# RTL8710AF register map
Vendor: Realtek Semiconductor; Series: Ameba; File version: 0.1
CPU: CM3 r0p0, little endian, no MPU, no FPU, vendor SysTick, 4 interrupt priority bits
Registers are 32-bit, read-write, reset 0x0 unless marked. A register's access mark holds for its fields unless they carry their own. Offsets are from the block's base; [hi:lo] are bit positions; {n}, {i} and the like mark numbered series; 'fields as' and 'values as' point back to an identical list.

## SYSCON — System Control Registers
Base 0x40000000
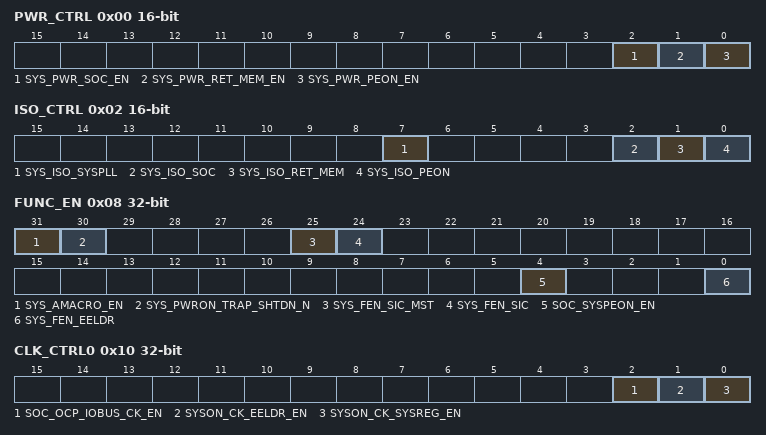
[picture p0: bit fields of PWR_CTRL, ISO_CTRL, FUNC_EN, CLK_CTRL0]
0x00 PWR_CTRL 16-bit
  [2] SYS_PWR_SOC_EN, [1] SYS_PWR_RET_MEM_EN, [0] SYS_PWR_PEON_EN
0x02 ISO_CTRL 16-bit
  [7] SYS_ISO_SYSPLL, [2] SYS_ISO_SOC, [1] SYS_ISO_RET_MEM, [0] SYS_ISO_PEON
0x08 FUNC_EN
  [31] SYS_AMACRO_EN, [30] SYS_PWRON_TRAP_SHTDN_N, [25] SYS_FEN_SIC_MST, [24] SYS_FEN_SIC, [4] SOC_SYSPEON_EN, [0] SYS_FEN_EELDR
0x10 CLK_CTRL0
  [2] SOC_OCP_IOBUS_CK_EN, [1] SYSON_CK_EELDR_EN, [0] SYSON_CK_SYSREG_EN
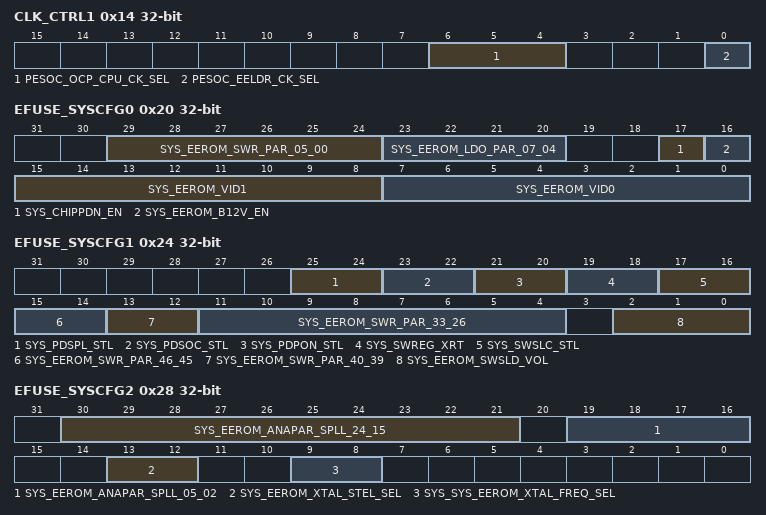
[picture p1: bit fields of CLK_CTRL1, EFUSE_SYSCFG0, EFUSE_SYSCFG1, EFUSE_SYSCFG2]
0x14 CLK_CTRL1
  [6:4] PESOC_OCP_CPU_CK_SEL, [0] PESOC_EELDR_CK_SEL
0x20 EFUSE_SYSCFG0
  [29:24] SYS_EEROM_SWR_PAR_05_00, [23:20] SYS_EEROM_LDO_PAR_07_04, [17] SYS_CHIPPDN_EN, [16] SYS_EEROM_B12V_EN, [15:8] SYS_EEROM_VID1, [7:0] SYS_EEROM_VID0
0x24 EFUSE_SYSCFG1
  [25:24] SYS_PDSPL_STL, [23:22] SYS_PDSOC_STL, [21:20] SYS_PDPON_STL, [19:18] SYS_SWREG_XRT, [17:16] SYS_SWSLC_STL, [15:14] SYS_EEROM_SWR_PAR_46_45, [13:12] SYS_EEROM_SWR_PAR_40_39, [11:4] SYS_EEROM_SWR_PAR_33_26, [2:0] SYS_EEROM_SWSLD_VOL
0x28 EFUSE_SYSCFG2
  [30:21] SYS_EEROM_ANAPAR_SPLL_24_15, [19:16] SYS_EEROM_ANAPAR_SPLL_05_02, [13:12] SYS_EEROM_XTAL_STEL_SEL, [9:8] SYS_SYS_EEROM_XTAL_FREQ_SEL
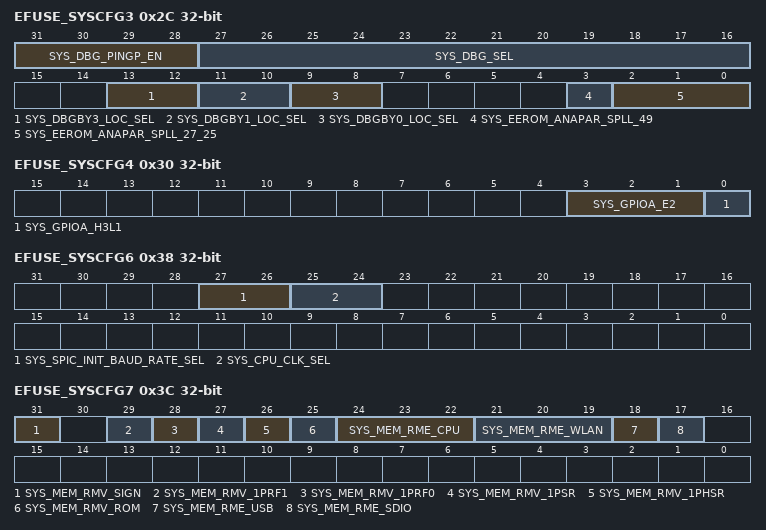
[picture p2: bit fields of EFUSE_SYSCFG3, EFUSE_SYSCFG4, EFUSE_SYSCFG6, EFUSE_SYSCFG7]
0x2C EFUSE_SYSCFG3
  [31:28] SYS_DBG_PINGP_EN, [27:16] SYS_DBG_SEL, [13:12] SYS_DBGBY3_LOC_SEL, [11:10] SYS_DBGBY1_LOC_SEL, [9:8] SYS_DBGBY0_LOC_SEL, [3] SYS_EEROM_ANAPAR_SPLL_49, [2:0] SYS_EEROM_ANAPAR_SPLL_27_25
0x30 EFUSE_SYSCFG4
  [3:1] SYS_GPIOA_E2, [0] SYS_GPIOA_H3L1
0x34 EFUSE_SYSCFG5
0x38 EFUSE_SYSCFG6
  [27:26] SYS_SPIC_INIT_BAUD_RATE_SEL, [25:24] SYS_CPU_CLK_SEL
0x3C EFUSE_SYSCFG7
  [31] SYS_MEM_RMV_SIGN, [29] SYS_MEM_RMV_1PRF1, [28] SYS_MEM_RMV_1PRF0, [27] SYS_MEM_RMV_1PSR, [26] SYS_MEM_RMV_1PHSR, [25] SYS_MEM_RMV_ROM, [24:22] SYS_MEM_RME_CPU, [21:19] SYS_MEM_RME_WLAN, [18] SYS_MEM_RME_USB, [17] SYS_MEM_RME_SDIO
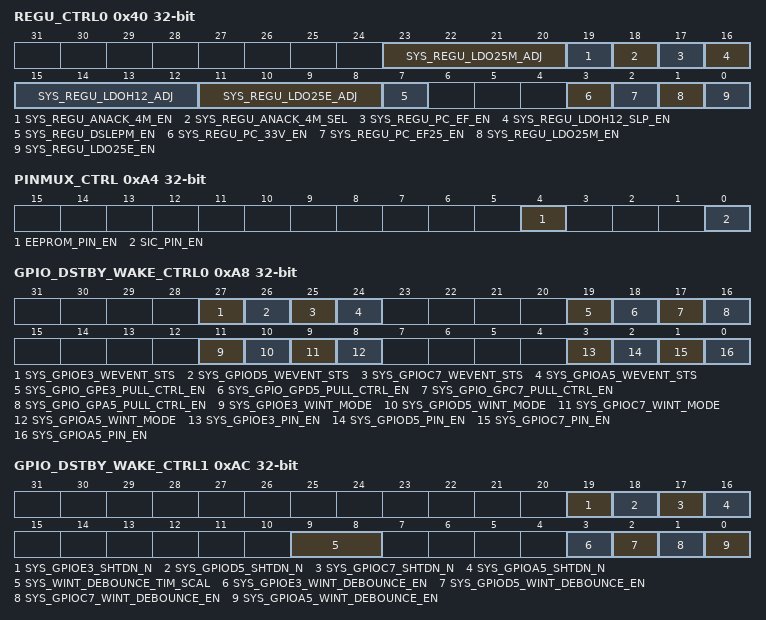
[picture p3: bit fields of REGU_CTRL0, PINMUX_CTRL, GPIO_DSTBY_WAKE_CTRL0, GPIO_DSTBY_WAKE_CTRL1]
0x40 REGU_CTRL0
  [23:20] SYS_REGU_LDO25M_ADJ, [19] SYS_REGU_ANACK_4M_EN, [18] SYS_REGU_ANACK_4M_SEL, [17] SYS_REGU_PC_EF_EN, [16] SYS_REGU_LDOH12_SLP_EN, [15:12] SYS_REGU_LDOH12_ADJ, [11:8] SYS_REGU_LDO25E_ADJ, [7] SYS_REGU_DSLEPM_EN, [3] SYS_REGU_PC_33V_EN, [2] SYS_REGU_PC_EF25_EN, [1] SYS_REGU_LDO25M_EN, [0] SYS_REGU_LDO25E_EN
0x48 SWR_CTRL0
0x4C SWR_CTRL1
0x60 XTAL_CTRL0
0x64 XTAL_CTRL1
{0x70+4i} SYSPLL_CTRL{i} (i=0..2)
0x90 ANA_TIM_CTRL
0x94 DSLP_TIM_CTRL
0x98 DSLP_TIM_CAL_CTRL
0xA0 DEBUG_CTRL
  [0] SYS_DBG_PIN_EN
0xA4 PINMUX_CTRL
  [4] EEPROM_PIN_EN, [0] SIC_PIN_EN
0xA8 GPIO_DSTBY_WAKE_CTRL0
  [27] SYS_GPIOE3_WEVENT_STS, [26] SYS_GPIOD5_WEVENT_STS, [25] SYS_GPIOC7_WEVENT_STS, [24] SYS_GPIOA5_WEVENT_STS, [19] SYS_GPIO_GPE3_PULL_CTRL_EN, [18] SYS_GPIO_GPD5_PULL_CTRL_EN, [17] SYS_GPIO_GPC7_PULL_CTRL_EN, [16] SYS_GPIO_GPA5_PULL_CTRL_EN, [11] SYS_GPIOE3_WINT_MODE, [10] SYS_GPIOD5_WINT_MODE, [9] SYS_GPIOC7_WINT_MODE, [8] SYS_GPIOA5_WINT_MODE, [3] SYS_GPIOE3_PIN_EN, [2] SYS_GPIOD5_PIN_EN, [1] SYS_GPIOC7_PIN_EN, [0] SYS_GPIOA5_PIN_EN
0xAC GPIO_DSTBY_WAKE_CTRL1
  [19] SYS_GPIOE3_SHTDN_N, [18] SYS_GPIOD5_SHTDN_N, [17] SYS_GPIOC7_SHTDN_N, [16] SYS_GPIOA5_SHTDN_N, [9:8] SYS_WINT_DEBOUNCE_TIM_SCAL, [3] SYS_GPIOE3_WINT_DEBOUNCE_EN, [2] SYS_GPIOD5_WINT_DEBOUNCE_EN, [1] SYS_GPIOC7_WINT_DEBOUNCE_EN, [0] SYS_GPIOA5_WINT_DEBOUNCE_EN
0xBC DEBUG_REG
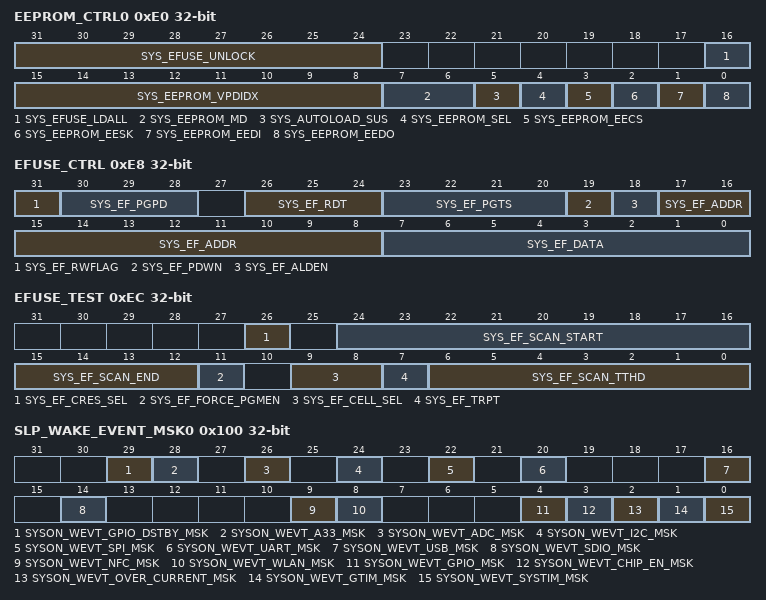
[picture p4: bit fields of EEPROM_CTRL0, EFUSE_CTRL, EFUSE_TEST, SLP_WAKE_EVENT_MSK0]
0xE0 EEPROM_CTRL0
  [31:24] SYS_EFUSE_UNLOCK, [16] SYS_EFUSE_LDALL, [15:8] SYS_EEPROM_VPDIDX, [7:6] SYS_EEPROM_MD, [5] SYS_AUTOLOAD_SUS, [4] SYS_EEPROM_SEL, [3] SYS_EEPROM_EECS, [2] SYS_EEPROM_EESK, [1] SYS_EEPROM_EEDI, [0] SYS_EEPROM_EEDO
0xE4 EEPROM_CTRL1
  [31:0] SYS_EEPROM_VPD
0xE8 EFUSE_CTRL
  [31] SYS_EF_RWFLAG, [30:28] SYS_EF_PGPD, [26:24] SYS_EF_RDT, [23:20] SYS_EF_PGTS, [19] SYS_EF_PDWN, [18] SYS_EF_ALDEN, [17:8] SYS_EF_ADDR, [7:0] SYS_EF_DATA
0xEC EFUSE_TEST
  [26] SYS_EF_CRES_SEL, [24:16] SYS_EF_SCAN_START, [15:12] SYS_EF_SCAN_END, [11] SYS_EF_FORCE_PGMEN, [9:8] SYS_EF_CELL_SEL, [7] SYS_EF_TRPT, [6:0] SYS_EF_SCAN_TTHD
{0xF0+4i} DSTBY_INFO{i} (i=0..3)
0x100 SLP_WAKE_EVENT_MSK0
  [29] SYSON_WEVT_GPIO_DSTBY_MSK, [28] SYSON_WEVT_A33_MSK, [26] SYSON_WEVT_ADC_MSK, [24] SYSON_WEVT_I2C_MSK, [22] SYSON_WEVT_SPI_MSK, [20] SYSON_WEVT_UART_MSK, [16] SYSON_WEVT_USB_MSK, [14] SYSON_WEVT_SDIO_MSK, [9] SYSON_WEVT_NFC_MSK, [8] SYSON_WEVT_WLAN_MSK, [4] SYSON_WEVT_GPIO_MSK, [3] SYSON_WEVT_CHIP_EN_MSK, [2] SYSON_WEVT_OVER_CURRENT_MSK, [1] SYSON_WEVT_GTIM_MSK, [0] SYSON_WEVT_SYSTIM_MSK
0x104 SLP_WAKE_EVENT_MSK1
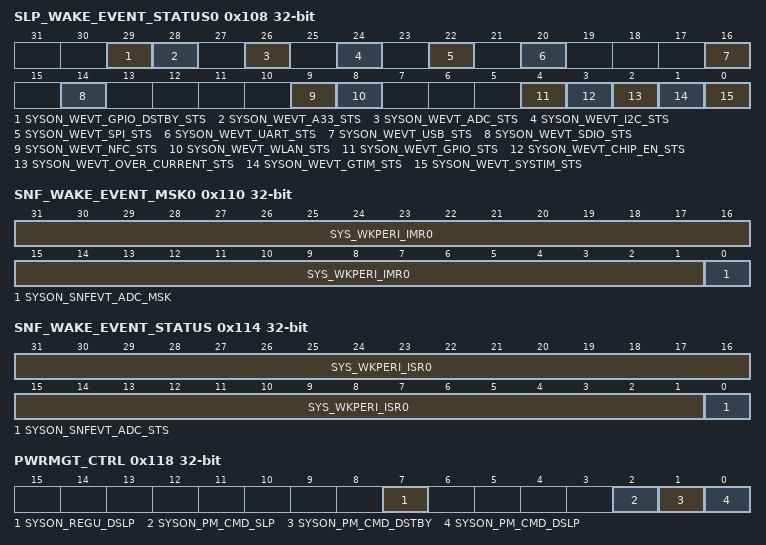
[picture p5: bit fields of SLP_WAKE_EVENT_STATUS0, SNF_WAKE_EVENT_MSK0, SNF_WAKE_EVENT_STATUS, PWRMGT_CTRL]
0x108 SLP_WAKE_EVENT_STATUS0
  [29] SYSON_WEVT_GPIO_DSTBY_STS, [28] SYSON_WEVT_A33_STS, [26] SYSON_WEVT_ADC_STS, [24] SYSON_WEVT_I2C_STS, [22] SYSON_WEVT_SPI_STS, [20] SYSON_WEVT_UART_STS, [16] SYSON_WEVT_USB_STS, [14] SYSON_WEVT_SDIO_STS, [9] SYSON_WEVT_NFC_STS, [8] SYSON_WEVT_WLAN_STS, [4] SYSON_WEVT_GPIO_STS, [3] SYSON_WEVT_CHIP_EN_STS, [2] SYSON_WEVT_OVER_CURRENT_STS, [1] SYSON_WEVT_GTIM_STS, [0] SYSON_WEVT_SYSTIM_STS
0x10C SLP_WAKE_EVENT_STATUS1
0x110 SNF_WAKE_EVENT_MSK0
  [31:1] SYS_WKPERI_IMR0, [0] SYSON_SNFEVT_ADC_MSK
0x114 SNF_WAKE_EVENT_STATUS
  [31:1] SYS_WKPERI_ISR0, [0] SYSON_SNFEVT_ADC_STS
0x118 PWRMGT_CTRL
  [7] SYSON_REGU_DSLP, [2] SYSON_PM_CMD_SLP, [1] SYSON_PM_CMD_DSTBY, [0] SYSON_PM_CMD_DSLP
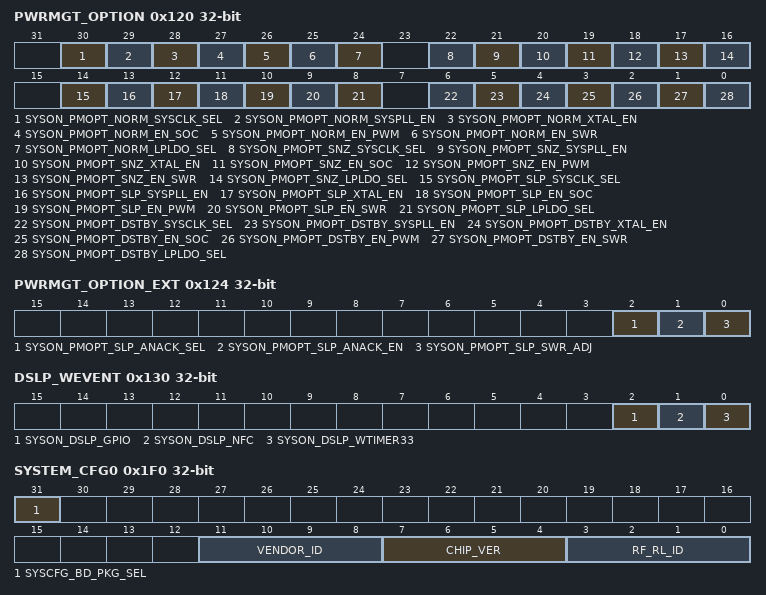
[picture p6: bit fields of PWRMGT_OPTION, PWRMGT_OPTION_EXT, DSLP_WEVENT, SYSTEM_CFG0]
0x120 PWRMGT_OPTION
  [30] SYSON_PMOPT_NORM_SYSCLK_SEL, [29] SYSON_PMOPT_NORM_SYSPLL_EN, [28] SYSON_PMOPT_NORM_XTAL_EN, [27] SYSON_PMOPT_NORM_EN_SOC, [26] SYSON_PMOPT_NORM_EN_PWM, [25] SYSON_PMOPT_NORM_EN_SWR, [24] SYSON_PMOPT_NORM_LPLDO_SEL, [22] SYSON_PMOPT_SNZ_SYSCLK_SEL, [21] SYSON_PMOPT_SNZ_SYSPLL_EN, [20] SYSON_PMOPT_SNZ_XTAL_EN, [19] SYSON_PMOPT_SNZ_EN_SOC, [18] SYSON_PMOPT_SNZ_EN_PWM, [17] SYSON_PMOPT_SNZ_EN_SWR, [16] SYSON_PMOPT_SNZ_LPLDO_SEL, [14] SYSON_PMOPT_SLP_SYSCLK_SEL, [13] SYSON_PMOPT_SLP_SYSPLL_EN, [12] SYSON_PMOPT_SLP_XTAL_EN, [11] SYSON_PMOPT_SLP_EN_SOC, [10] SYSON_PMOPT_SLP_EN_PWM, [9] SYSON_PMOPT_SLP_EN_SWR, [8] SYSON_PMOPT_SLP_LPLDO_SEL, [6] SYSON_PMOPT_DSTBY_SYSCLK_SEL, [5] SYSON_PMOPT_DSTBY_SYSPLL_EN, [4] SYSON_PMOPT_DSTBY_XTAL_EN, [3] SYSON_PMOPT_DSTBY_EN_SOC, [2] SYSON_PMOPT_DSTBY_EN_PWM, [1] SYSON_PMOPT_DSTBY_EN_SWR, [0] SYSON_PMOPT_DSTBY_LPLDO_SEL
0x124 PWRMGT_OPTION_EXT
  [2] SYSON_PMOPT_SLP_ANACK_SEL, [1] SYSON_PMOPT_SLP_ANACK_EN, [0] SYSON_PMOPT_SLP_SWR_ADJ
0x130 DSLP_WEVENT
  [2] SYSON_DSLP_GPIO, [1] SYSON_DSLP_NFC, [0] SYSON_DSLP_WTIMER33
0x134 PERI_MONITOR
  [0] SYSON_ISO33_NFC
0x1F0 SYSTEM_CFG0
  [31] SYSCFG_BD_PKG_SEL, [11:8] VENDOR_ID, [7:4] CHIP_VER, [3:0] RF_RL_ID
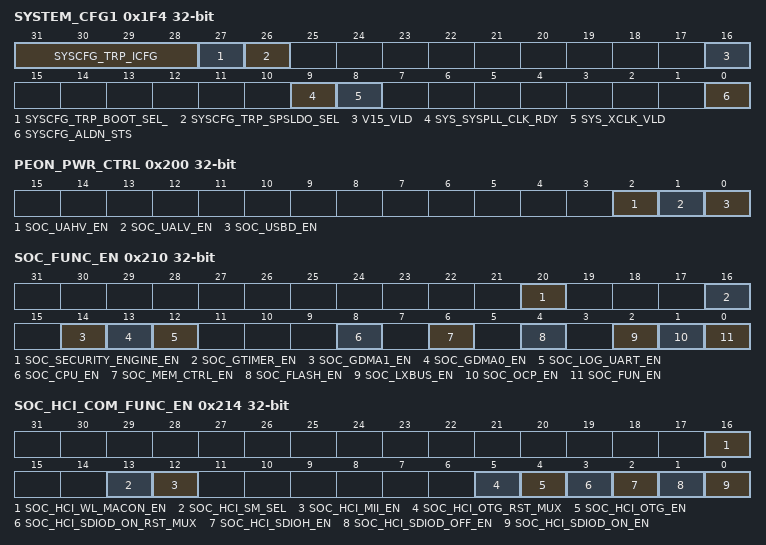
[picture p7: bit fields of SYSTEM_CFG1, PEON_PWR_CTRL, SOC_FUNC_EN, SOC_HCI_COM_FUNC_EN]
0x1F4 SYSTEM_CFG1
  [31:28] SYSCFG_TRP_ICFG, [27] SYSCFG_TRP_BOOT_SEL_, [26] SYSCFG_TRP_SPSLDO_SEL, [16] V15_VLD, [9] SYS_SYSPLL_CLK_RDY, [8] SYS_XCLK_VLD, [0] SYSCFG_ALDN_STS
0x1F8 SYSTEM_CFG2
0x200 PEON_PWR_CTRL
  [2] SOC_UAHV_EN, [1] SOC_UALV_EN, [0] SOC_USBD_EN
0x204 PON_ISO_CTRL
  [4] ISO_OSC32K_EN
0x210 SOC_FUNC_EN
  [20] SOC_SECURITY_ENGINE_EN, [16] SOC_GTIMER_EN, [14] SOC_GDMA1_EN, [13] SOC_GDMA0_EN, [12] SOC_LOG_UART_EN, [8] SOC_CPU_EN, [6] SOC_MEM_CTRL_EN, [4] SOC_FLASH_EN, [2] SOC_LXBUS_EN, [1] SOC_OCP_EN, [0] SOC_FUN_EN
0x214 SOC_HCI_COM_FUNC_EN
  [16] SOC_HCI_WL_MACON_EN, [13] SOC_HCI_SM_SEL, [12] SOC_HCI_MII_EN, [5] SOC_HCI_OTG_RST_MUX, [4] SOC_HCI_OTG_EN, [3] SOC_HCI_SDIOD_ON_RST_MUX, [2] SOC_HCI_SDIOH_EN, [1] SOC_HCI_SDIOD_OFF_EN, [0] SOC_HCI_SDIOD_ON_EN
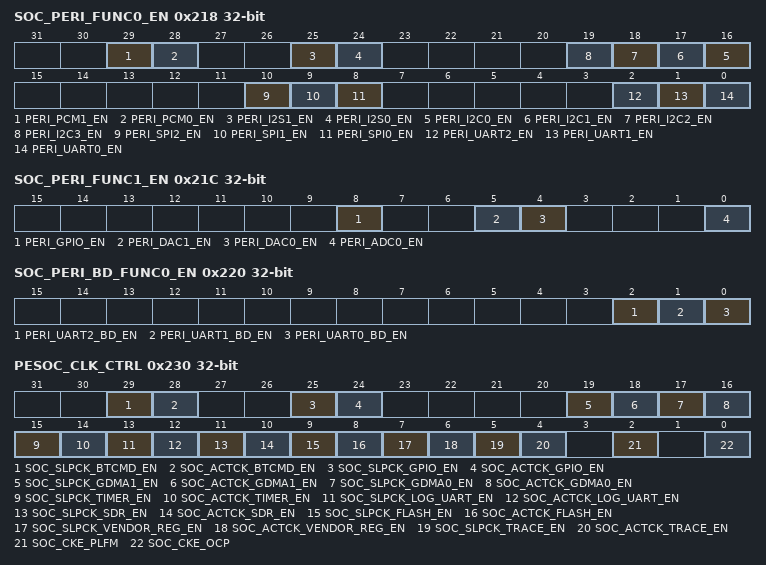
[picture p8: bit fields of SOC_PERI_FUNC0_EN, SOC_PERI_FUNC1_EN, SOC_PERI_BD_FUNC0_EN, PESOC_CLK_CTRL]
0x218 SOC_PERI_FUNC0_EN
  [29] PERI_PCM1_EN, [28] PERI_PCM0_EN, [25] PERI_I2S1_EN, [24] PERI_I2S0_EN, [n+16] PERI_I2C{n}_EN (n=0..3), [10] PERI_SPI2_EN, [9] PERI_SPI1_EN, [8] PERI_SPI0_EN, [2] PERI_UART2_EN, [1] PERI_UART1_EN, [0] PERI_UART0_EN
0x21C SOC_PERI_FUNC1_EN
  [8] PERI_GPIO_EN, [5] PERI_DAC1_EN, [4] PERI_DAC0_EN, [0] PERI_ADC0_EN
0x220 SOC_PERI_BD_FUNC0_EN
  [2] PERI_UART2_BD_EN, [1] PERI_UART1_BD_EN, [0] PERI_UART0_BD_EN
0x230 PESOC_CLK_CTRL
  [29] SOC_SLPCK_BTCMD_EN, [28] SOC_ACTCK_BTCMD_EN, [25] SOC_SLPCK_GPIO_EN, [24] SOC_ACTCK_GPIO_EN, [19] SOC_SLPCK_GDMA1_EN, [18] SOC_ACTCK_GDMA1_EN, [17] SOC_SLPCK_GDMA0_EN, [16] SOC_ACTCK_GDMA0_EN, [15] SOC_SLPCK_TIMER_EN, [14] SOC_ACTCK_TIMER_EN, [13] SOC_SLPCK_LOG_UART_EN, [12] SOC_ACTCK_LOG_UART_EN, [11] SOC_SLPCK_SDR_EN, [10] SOC_ACTCK_SDR_EN, [9] SOC_SLPCK_FLASH_EN, [8] SOC_ACTCK_FLASH_EN, [7] SOC_SLPCK_VENDOR_REG_EN, [6] SOC_ACTCK_VENDOR_REG_EN, [5] SOC_SLPCK_TRACE_EN, [4] SOC_ACTCK_TRACE_EN, [2] SOC_CKE_PLFM, [0] SOC_CKE_OCP
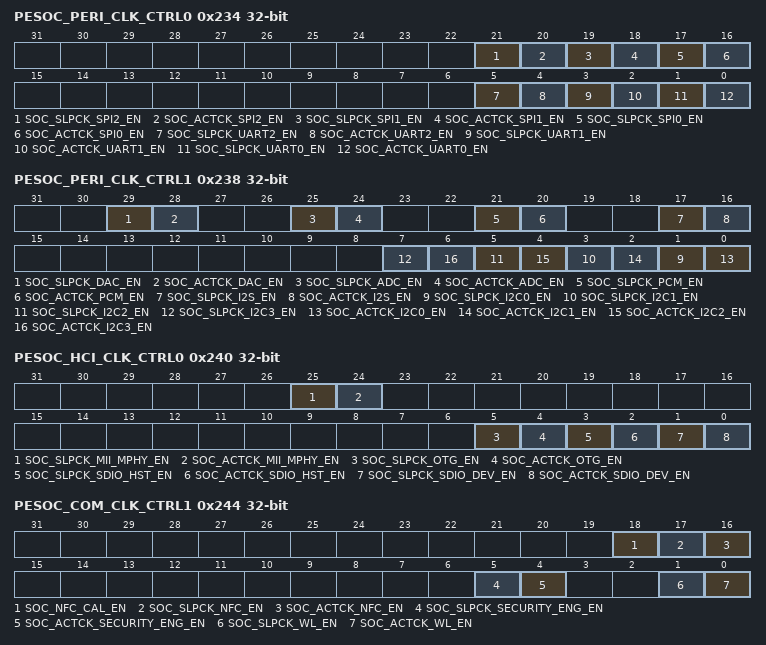
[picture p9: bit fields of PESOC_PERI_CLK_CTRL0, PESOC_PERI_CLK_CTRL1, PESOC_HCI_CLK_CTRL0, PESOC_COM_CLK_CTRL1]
0x234 PESOC_PERI_CLK_CTRL0
  [21] SOC_SLPCK_SPI2_EN, [20] SOC_ACTCK_SPI2_EN, [19] SOC_SLPCK_SPI1_EN, [18] SOC_ACTCK_SPI1_EN, [17] SOC_SLPCK_SPI0_EN, [16] SOC_ACTCK_SPI0_EN, [5] SOC_SLPCK_UART2_EN, [4] SOC_ACTCK_UART2_EN, [3] SOC_SLPCK_UART1_EN, [2] SOC_ACTCK_UART1_EN, [1] SOC_SLPCK_UART0_EN, [0] SOC_ACTCK_UART0_EN
0x238 PESOC_PERI_CLK_CTRL1
  [29] SOC_SLPCK_DAC_EN, [28] SOC_ACTCK_DAC_EN, [25] SOC_SLPCK_ADC_EN, [24] SOC_ACTCK_ADC_EN, [21] SOC_SLPCK_PCM_EN, [20] SOC_ACTCK_PCM_EN, [17] SOC_SLPCK_I2S_EN, [16] SOC_ACTCK_I2S_EN, [2n+1] SOC_SLPCK_I2C{n}_EN (n=0..3), [2n] SOC_ACTCK_I2C{n}_EN (n=0..3)
0x23C PESOC_CLK_CTRL3
0x240 PESOC_HCI_CLK_CTRL0
  [25] SOC_SLPCK_MII_MPHY_EN, [24] SOC_ACTCK_MII_MPHY_EN, [5] SOC_SLPCK_OTG_EN, [4] SOC_ACTCK_OTG_EN, [3] SOC_SLPCK_SDIO_HST_EN, [2] SOC_ACTCK_SDIO_HST_EN, [1] SOC_SLPCK_SDIO_DEV_EN, [0] SOC_ACTCK_SDIO_DEV_EN
0x244 PESOC_COM_CLK_CTRL1
  [18] SOC_NFC_CAL_EN, [17] SOC_SLPCK_NFC_EN, [16] SOC_ACTCK_NFC_EN, [5] SOC_SLPCK_SECURITY_ENG_EN, [4] SOC_ACTCK_SECURITY_ENG_EN, [1] SOC_SLPCK_WL_EN, [0] SOC_ACTCK_WL_EN
0x248 PESOC_HW_ENG_CLK_CTRL
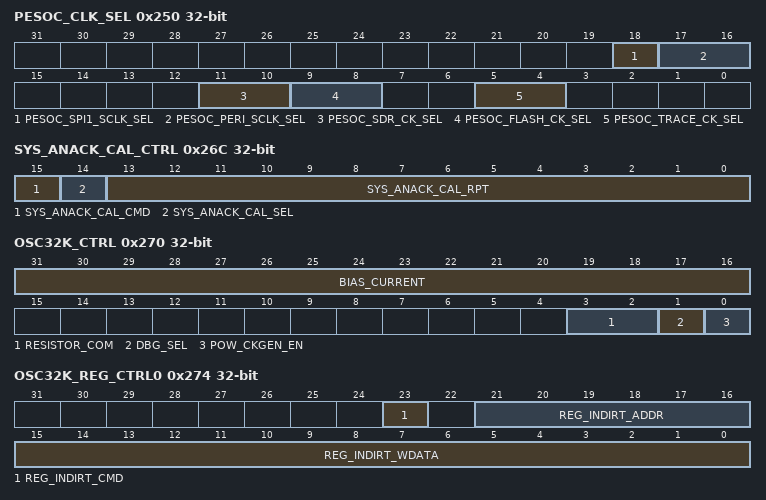
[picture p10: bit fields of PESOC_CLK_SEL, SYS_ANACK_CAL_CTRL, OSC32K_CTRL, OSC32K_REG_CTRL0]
0x250 PESOC_CLK_SEL
  [18] PESOC_SPI1_SCLK_SEL, [17:16] PESOC_PERI_SCLK_SEL, [11:10] PESOC_SDR_CK_SEL, [9:8] PESOC_FLASH_CK_SEL, [5:4] PESOC_TRACE_CK_SEL
0x26C SYS_ANACK_CAL_CTRL
  [15] SYS_ANACK_CAL_CMD, [14] SYS_ANACK_CAL_SEL, [13:0] SYS_ANACK_CAL_RPT
0x270 OSC32K_CTRL
  [31:16] BIAS_CURRENT, [3:2] RESISTOR_COM, [1] DBG_SEL, [0] POW_CKGEN_EN
0x274 OSC32K_REG_CTRL0
  [23] REG_INDIRT_CMD, [21:16] REG_INDIRT_ADDR, [15:0] REG_INDIRT_WDATA wo
0x278 OSC32K_REG_CTRL1
  [15:0] REG_INDIRT_RDATA ro
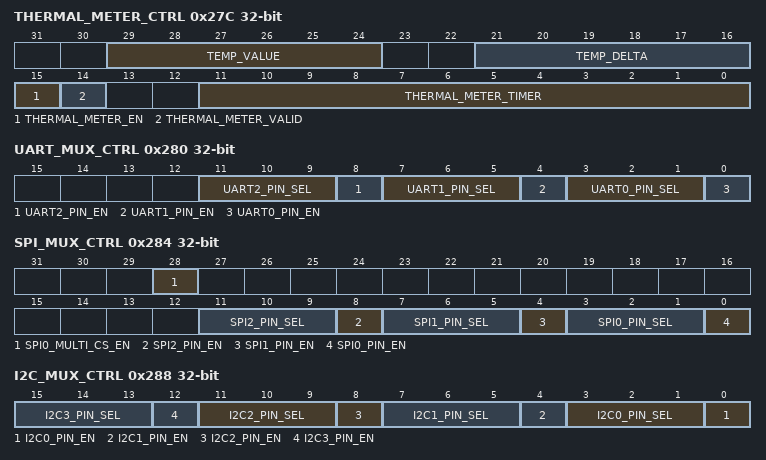
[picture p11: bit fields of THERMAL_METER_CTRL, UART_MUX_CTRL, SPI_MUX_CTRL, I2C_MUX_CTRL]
0x27C THERMAL_METER_CTRL
  [29:24] TEMP_VALUE, [21:16] TEMP_DELTA, [15] THERMAL_METER_EN, [14] THERMAL_METER_VALID, [11:0] THERMAL_METER_TIMER
0x280 UART_MUX_CTRL
  [11:9] UART2_PIN_SEL, [8] UART2_PIN_EN, [7:5] UART1_PIN_SEL, [4] UART1_PIN_EN, [3:1] UART0_PIN_SEL, [0] UART0_PIN_EN
0x284 SPI_MUX_CTRL
  [28] SPI0_MULTI_CS_EN, [11:9] SPI2_PIN_SEL, [8] SPI2_PIN_EN, [7:5] SPI1_PIN_SEL, [4] SPI1_PIN_EN, [3:1] SPI0_PIN_SEL, [0] SPI0_PIN_EN
0x288 I2C_MUX_CTRL
  [4n+3:4n+1] I2C{n}_PIN_SEL (n=0..3), [4n] I2C{n}_PIN_EN (n=0..3)
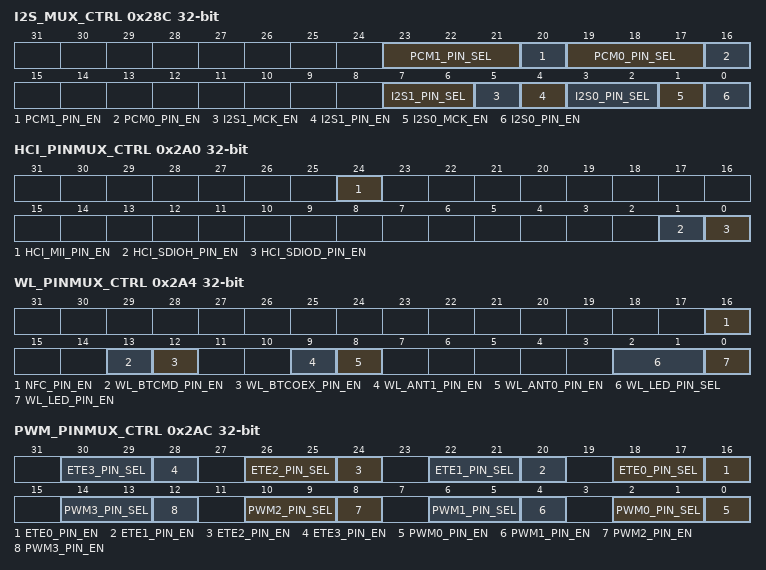
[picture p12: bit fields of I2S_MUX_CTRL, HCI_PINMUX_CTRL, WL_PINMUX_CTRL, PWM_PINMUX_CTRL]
0x28C I2S_MUX_CTRL
  [23:21] PCM1_PIN_SEL, [20] PCM1_PIN_EN, [19:17] PCM0_PIN_SEL, [16] PCM0_PIN_EN, [7:6] I2S1_PIN_SEL, [5] I2S1_MCK_EN, [4] I2S1_PIN_EN, [3:2] I2S0_PIN_SEL, [1] I2S0_MCK_EN, [0] I2S0_PIN_EN
0x2A0 HCI_PINMUX_CTRL
  [24] HCI_MII_PIN_EN, [1] HCI_SDIOH_PIN_EN, [0] HCI_SDIOD_PIN_EN
0x2A4 WL_PINMUX_CTRL
  [16] NFC_PIN_EN, [13] WL_BTCMD_PIN_EN, [12] WL_BTCOEX_PIN_EN, [9] WL_ANT1_PIN_EN, [8] WL_ANT0_PIN_EN, [2:1] WL_LED_PIN_SEL, [0] WL_LED_PIN_EN
0x2A8 BT_PINMUX_CTRL
0x2AC PWM_PINMUX_CTRL
  [4n+18:4n+17] ETE{n}_PIN_SEL (n=0..3), [4n+16] ETE{n}_PIN_EN (n=0..3), [4n+2:4n+1] PWM{n}_PIN_SEL (n=0..3), [4n] PWM{n}_PIN_EN (n=0..3)
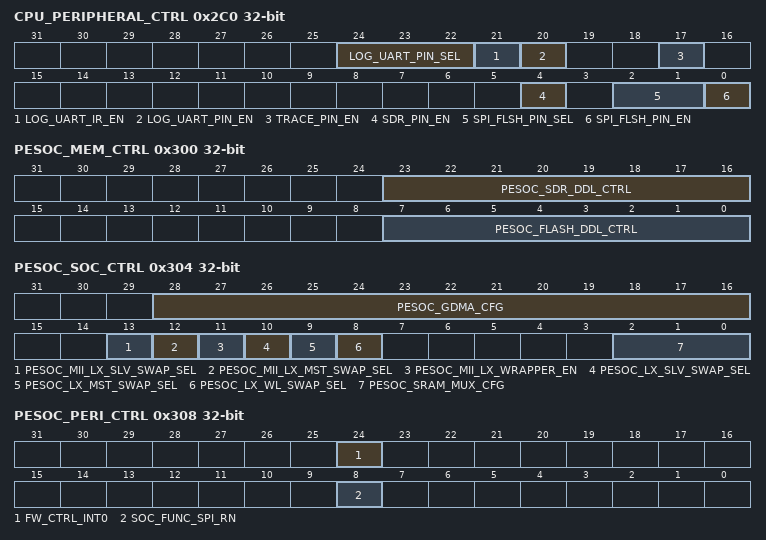
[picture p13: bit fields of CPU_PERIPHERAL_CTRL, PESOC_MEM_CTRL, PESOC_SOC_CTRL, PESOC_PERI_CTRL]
0x2C0 CPU_PERIPHERAL_CTRL
  [24:22] LOG_UART_PIN_SEL, [21] LOG_UART_IR_EN, [20] LOG_UART_PIN_EN, [17] TRACE_PIN_EN, [4] SDR_PIN_EN, [2:1] SPI_FLSH_PIN_SEL, [0] SPI_FLSH_PIN_EN
0x2E0 HCI_CTRL_STATUS_0
0x2E4 HCI_CTRL_STATUS_1
0x300 PESOC_MEM_CTRL
  [23:16] PESOC_SDR_DDL_CTRL, [7:0] PESOC_FLASH_DDL_CTRL
0x304 PESOC_SOC_CTRL
  [28:16] PESOC_GDMA_CFG, [13] PESOC_MII_LX_SLV_SWAP_SEL, [12] PESOC_MII_LX_MST_SWAP_SEL, [11] PESOC_MII_LX_WRAPPER_EN, [10] PESOC_LX_SLV_SWAP_SEL, [9] PESOC_LX_MST_SWAP_SEL, [8] PESOC_LX_WL_SWAP_SEL, [2:0] PESOC_SRAM_MUX_CFG
0x308 PESOC_PERI_CTRL
  [24] FW_CTRL_INT0, [8] SOC_FUNC_SPI_RN
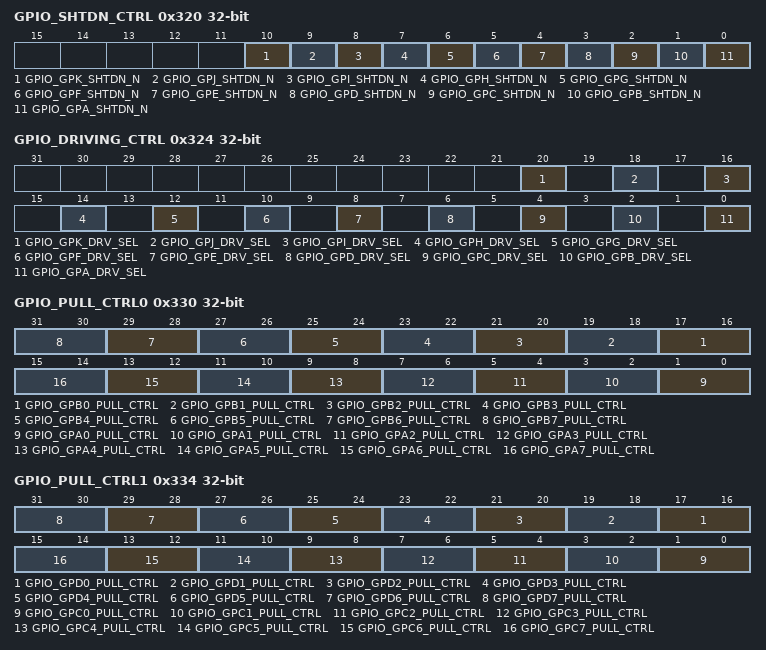
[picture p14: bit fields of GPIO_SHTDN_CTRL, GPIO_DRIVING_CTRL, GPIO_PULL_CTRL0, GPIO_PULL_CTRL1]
0x320 GPIO_SHTDN_CTRL
  [10] GPIO_GPK_SHTDN_N, [9] GPIO_GPJ_SHTDN_N, [8] GPIO_GPI_SHTDN_N, [7] GPIO_GPH_SHTDN_N, [6] GPIO_GPG_SHTDN_N, [5] GPIO_GPF_SHTDN_N, [4] GPIO_GPE_SHTDN_N, [3] GPIO_GPD_SHTDN_N, [2] GPIO_GPC_SHTDN_N, [1] GPIO_GPB_SHTDN_N, [0] GPIO_GPA_SHTDN_N
0x324 GPIO_DRIVING_CTRL
  [20] GPIO_GPK_DRV_SEL, [18] GPIO_GPJ_DRV_SEL, [16] GPIO_GPI_DRV_SEL, [14] GPIO_GPH_DRV_SEL, [12] GPIO_GPG_DRV_SEL, [10] GPIO_GPF_DRV_SEL, [8] GPIO_GPE_DRV_SEL, [6] GPIO_GPD_DRV_SEL, [4] GPIO_GPC_DRV_SEL, [2] GPIO_GPB_DRV_SEL, [0] GPIO_GPA_DRV_SEL
0x330 GPIO_PULL_CTRL0
  [all] fields
    0=HIGHZ (High-impedence (floating)); 1=PULL_LOW (Pulled low); 2=PULL_HIGH (Pulled high)
  [2n+17:2n+16] GPIO_GPB{n}_PULL_CTRL (n=0..7)
  [2n+1:2n] GPIO_GPA{n}_PULL_CTRL (n=0..7)
0x334 GPIO_PULL_CTRL1
  [all] fields
    values as the fields of GPIO_PULL_CTRL0
  [2n+17:2n+16] GPIO_GPD{n}_PULL_CTRL (n=0..7)
  [2n+1:2n] GPIO_GPC{n}_PULL_CTRL (n=0..7)
0x338 GPIO_PULL_CTRL2
  [all] fields
    values as the fields of GPIO_PULL_CTRL0
  [2n+17:2n+16] GPIO_GPF{n}_PULL_CTRL (n=0..7)
  [2n+1:2n] GPIO_GPE{n}_PULL_CTRL (n=0..7)
0x33C GPIO_PULL_CTRL3
  [all] fields
    values as the fields of GPIO_PULL_CTRL0
  [2n+17:2n+16] GPIO_GPH{n}_PULL_CTRL (n=0..7)
  [2n+1:2n] GPIO_GPG{n}_PULL_CTRL (n=0..7)
0x340 GPIO_PULL_CTRL4
  [all] fields
    values as the fields of GPIO_PULL_CTRL0
  [2n+17:2n+16] GPIO_GPJ{n}_PULL_CTRL (n=0..7)
  [2n+1:2n] GPIO_GPI{n}_PULL_CTRL (n=0..7)
0x344 GPIO_PULL_CTRL5
  [all] fields
    values as the fields of GPIO_PULL_CTRL0
  [21:20] GPIO_GPEA_PULL_CTRL
  [19:18] GPIO_GPE9_PULL_CTRL
  [17:16] GPIO_GPE8_PULL_CTRL
  [13:12] GPIO_GPK7_PULL_CTRL
  [2n+1:2n] GPIO_GPK{n}_PULL_CTRL (n=0..5)
0x348 GPIO_PULL_CTRL6
  [all] fields
    values as the fields of GPIO_PULL_CTRL0
  [19:18] GPIO_GPD9_PULL_CTRL
  [17:16] GPIO_GPD8_PULL_CTRL
  [3:2] GPIO_GPC9_PULL_CTRL
  [1:0] GPIO_GPC8_PULL_CTRL
{0x360+4i} PERI_PWM{i}_CTRL (i=0..3)
  [31] PERI_PWM{i}_EN, [27:24] PERI_PWM{i}_GT_SEL, [21:12] PERI_PWM{i}_DUTY, [9:0] PERI_PWM{i}_PERIOD
0x370 PERI_TIM_EVT_CTRL
  [8n+7] PERI_GT_EVT{n}_EN (n=0..3), [8n+6:8n+4] PERI_GT_EVT{n}_SRC_SEL (n=0..3), [8n+3:8n] PERI_GT_EVT{n}_PULSE_DUR (n=0..3)
0x374 PERI_EGTIM_CTRL
  [13:12] PERI_EGTIM_PIN_GROUP2_OPT_SEL, [11:10] PERI_EGTIM_PIN_GROUP1_OPT_SEL, [9:8] PERI_EGTIM_PIN_GROUP0_OPT_SEL, [5:4] PERI_EGTIM_REF_SIG_SEL, [0] PERI_EGTIM_EN
0x3F0 PEON_CFG
0x3F4 PEON_STATUS
  [0] PEON_SDIO_ALDN

## Timer — Timer Control
Base 0x40002000
0x00 TIMER_LOAD_COUNT
0x04 TIMER_CURRENT_VAL — Current Value
0x08 TIMER_CTL_REG — Timer Control
  [3] TIMER_PWM — Select between PWM (1) and Timer (0) mode
  [2] TIMER_INTERRUPT_MASK
  [1] TIMER_MODE — Select between free running (0) and count (1) mode
  [0] TIMER_ENABLE — Enable flag
0x0C TIMER_EOI — Reading from this register returns b0, and clears the interrupt from PWM/Timer
  [0] EOI ro — End of Interrupt
0x10 TIMER_INT_STATUS — Post-masking interrupt status of PWM/Timer
  [0] INT_STATUS ro
0x14 TIMER_INTERVAL
0xA0 TIMERS_INT_STATUS — Timers Interrupt Status
0xA4 TIMERS_EOI — Timers End of Interrupt
0xA8 TIMERS_RAW_INT_STATUS — Timers raw interrupt status
0xAC TIMERS_COMP_VER ro — ASCII string representing the version number of the timers logic

## LOG_UART — UART for Log
Base 0x40003000
Same registers: UART0 0x40040000, UART1 0x40040800
0x00 DLL — Divisor Latch Low
0x04 IER_DLH — Interrupt Enable / Divisor Latch High
  [7:0] IER_DLH
0x08 IIR_FCR — Interrupt Identification / FIFO Control
  [7:0] IIR_FCR
0x0C LCR — Line Control Register
  [7] DLAB — Divisor Latch Access Bit
  [6] BC — Break Control Bit
  [5] STICK_PAR — Stick Parity
  [4] EPS — Even Parity Select: 0: Odd parity, 1: Even parity
  [3] PEN — Parity Enable
  [2] STOP — Number of stop bits: 0: No stop bit, 1: 1 stop bit
  [0] DLS — Data Length Select: 0 = 7bits, 1: 8bits
0x10 MCR — Modem Control Register
  [5] AFCE — Auto Flow Control Enable
  [1] RTS
  [0] DTR
0x14 LSR — Line Status Register
  [7] RFE — RX FIFO Error
  [6] TEMT — Transmitter Empty
  [5] THRE — Transmitter Holding Register Empty
  [4] BI — Break Interrupt error
  [3] FE — Framing Error
  [2] PE — Parity Error
  [1] OE — Overrun Error
  [0] DR — Data Ready
0x18 MSR — Modem Status Register
0x1C SCR — Scratch Pad
  [26:16] XFACTOR_ADJ
  [11:8] DBG_SEL — Debug port selection
  [7] RXBREAK_INT_STATUS — Write 1 to clear
0x20 STS
  [7:4] XFACTOR
  [3] RESET_RCV — Reset Uart Receiver
0x24 RECV_BUF_TRAN_HOLD — Receive Buffer / Transmission Hold
0x28 MISC_CTL — Misc Control
  [12:8] RXDMA_BURSTSIZE, [7:3] TXDMA_BURSTSIZE, [2] RXDMA_EN, [1] TXDMA_EN
0x3C DEBUG — UART Debug
